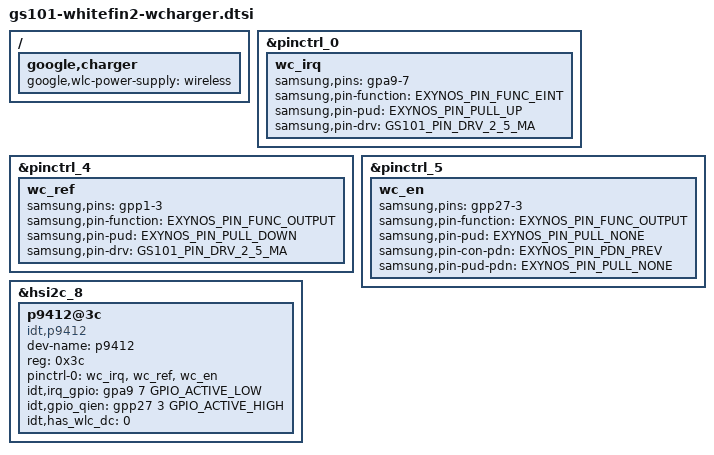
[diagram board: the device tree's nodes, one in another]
// SPDX-License-Identifier: GPL-2.0-only
/*
 * Copyright 2020 Google,LLC
 *
 * Wireless Charger device tree entries.
 */

#include <dt-bindings/pinctrl/samsung.h>
#include <dt-bindings/interrupt-controller/irq.h>

/* need to use an overlay until we remove dt patching from the bootloader */
/ {
	fragment@wlc {
		target-path = "/";
		__overlay__ {
			google,charger {
				google,wlc-power-supply = "wireless";
			};

		};
	};
};

&pinctrl_0 {
	/* XIENT_27 P9382 Wireless Charger Interrupt */
	wc_irq: wc_irq {
		samsung,pins = "gpa9-7"; /* QI_INT_R */
		samsung,pin-function = <EXYNOS_PIN_FUNC_EINT>;
		samsung,pin-pud = <EXYNOS_PIN_PULL_UP>;
		samsung,pin-drv = <GS101_PIN_DRV_2_5_MA>;
	};
};

&pinctrl_4 {
	wc_ref: wc_ref {
		samsung,pins = "gpp1-3";
		samsung,pin-function = <EXYNOS_PIN_FUNC_OUTPUT>;
		samsung,pin-pud = <EXYNOS_PIN_PULL_DOWN>;
		samsung,pin-drv = <GS101_PIN_DRV_2_5_MA>;
	};
};

&pinctrl_5 {
	/* XAPC_PWM_3 P9382 Wireless Charger Enable */
	wc_en: wc_en {
		samsung,pins = "gpp27-3"; /* QI_EN_L */
		samsung,pin-function = <EXYNOS_PIN_FUNC_OUTPUT>;
		samsung,pin-pud = <EXYNOS_PIN_PULL_NONE>;
		samsung,pin-con-pdn = <EXYNOS_PIN_PDN_PREV>;
		samsung,pin-pud-pdn = <EXYNOS_PIN_PULL_NONE>;
	};
};

&hsi2c_8 {
	#address-cells = <1>;
	#size-cells = <0>;
	status = "ok";

	p9412@3c {
		status = "ok";
		dev-name = "p9412";
		compatible = "idt,p9412";
		reg = <0x3c>;

		pinctrl-names = "default";
		pinctrl-0 = <&wc_irq &wc_ref &wc_en>;

		interrupt-names = "p9382_int";
		idt,irq_gpio = <&gpa9 7 GPIO_ACTIVE_LOW>;
		idt,gpio_qien = <&gpp27 3 GPIO_ACTIVE_HIGH>;
		idt,has_wlc_dc = <0>;
	};
};
